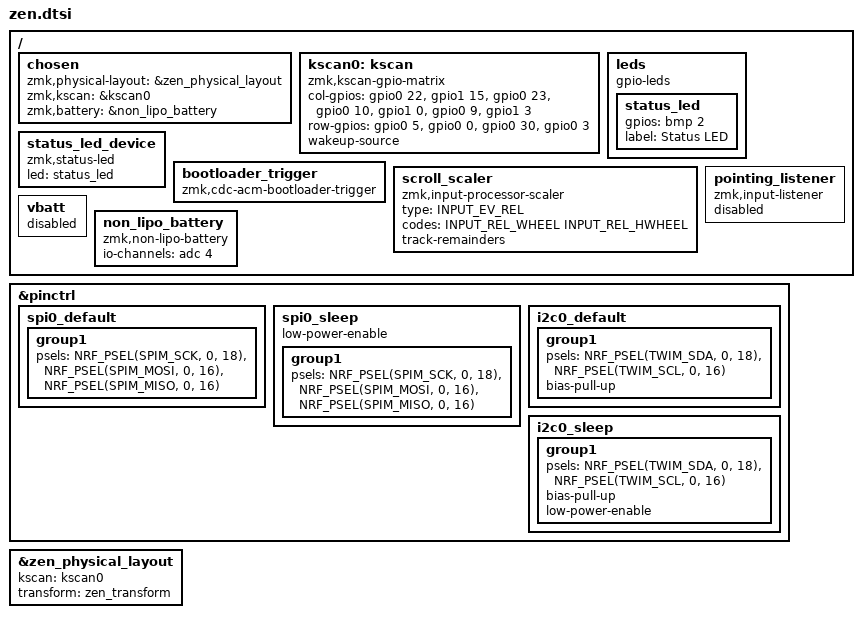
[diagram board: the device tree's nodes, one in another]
#include <zephyr/dt-bindings/gpio/nordic-nrf-gpio.h>
#include <dt-bindings/input/input-event-codes.h>
#include <dt-bindings/zmk/matrix_transform.h>
#include "zen_layouts.dtsi"
#include "zen_transform.dtsi"

/ {
    chosen {
        zmk,physical-layout = &zen_physical_layout;
        zmk,kscan = &kscan0;
        zmk,battery = &non_lipo_battery;
    };

    kscan0: kscan {
        compatible = "zmk,kscan-gpio-matrix";

        col-gpios
            = <&gpio0 22 (GPIO_ACTIVE_HIGH | GPIO_PULL_DOWN)>,
            <&gpio1 15   (GPIO_ACTIVE_HIGH | GPIO_PULL_DOWN)>,
            <&gpio0 23   (GPIO_ACTIVE_HIGH | GPIO_PULL_DOWN)>,
            <&gpio0 10   (GPIO_ACTIVE_HIGH | GPIO_PULL_DOWN)>,
            <&gpio1 0    (GPIO_ACTIVE_HIGH | GPIO_PULL_DOWN)>,
            <&gpio0 9    (GPIO_ACTIVE_HIGH | GPIO_PULL_DOWN)>,
            <&gpio1 3    (GPIO_ACTIVE_HIGH | GPIO_PULL_DOWN)>
            ;

        row-gpios
            = <&gpio0 5 (GPIO_ACTIVE_HIGH)>,
            <&gpio0 0  (GPIO_ACTIVE_HIGH)>,
            <&gpio0 30 (GPIO_ACTIVE_HIGH)>,
            <&gpio0 3  (GPIO_ACTIVE_HIGH)>
            ;

        wakeup-source;
    };

    leds {
        compatible = "gpio-leds";
        status_led: status_led {
            gpios = <&bmp 2 GPIO_ACTIVE_HIGH>;
            label = "Status LED";
        };
    };

    status_led_device: status_led_device {
        compatible = "zmk,status-led";
        led = <&status_led>;
    };

    bootloader_trigger: bootloader_trigger {
        compatible = "zmk,cdc-acm-bootloader-trigger";
    };

    scroll_scaler: scroll_scaler {
        compatible = "zmk,input-processor-scaler";
        #input-processor-cells = <2>;
        type = <INPUT_EV_REL>;
        codes = <INPUT_REL_WHEEL INPUT_REL_HWHEEL>;
        track-remainders;
    };

    pointing_listener: pointing_listener {
        compatible = "zmk,input-listener";
        status = "disabled";
    };

    vbatt: vbatt {
        status = "disabled";
    };

    non_lipo_battery: non_lipo_battery {
        compatible = "zmk,non-lipo-battery";
        io-channels = <&adc 4>;
    };
};

&pinctrl {
    spi0_default: spi0_default {
        group1 {
            psels = <NRF_PSEL(SPIM_SCK, 0, 18)>,
                    <NRF_PSEL(SPIM_MOSI, 0, 16)>,
                    <NRF_PSEL(SPIM_MISO, 0, 16)>;
        };
    };

    spi0_sleep: spi0_sleep {
        group1 {
            psels = <NRF_PSEL(SPIM_SCK, 0, 18)>,
                    <NRF_PSEL(SPIM_MOSI, 0, 16)>,
                    <NRF_PSEL(SPIM_MISO, 0, 16)>;
        };
        low-power-enable;
    };

    i2c0_default: i2c0_default {
        group1 {
            psels = <NRF_PSEL(TWIM_SDA, 0, 18)>,
                    <NRF_PSEL(TWIM_SCL, 0, 16)>;
            bias-pull-up;
        };
    };

    i2c0_sleep: i2c0_sleep {
        group1 {
            psels = <NRF_PSEL(TWIM_SDA, 0, 18)>,
                    <NRF_PSEL(TWIM_SCL, 0, 16)>;
            bias-pull-up;
            low-power-enable;
        };
    };
};

&zen_physical_layout {
    kscan = <&kscan0>;
    transform = <&zen_transform>;
};
